AUTOSAR XML (schema 4-0-3)
package /ComponentTypes
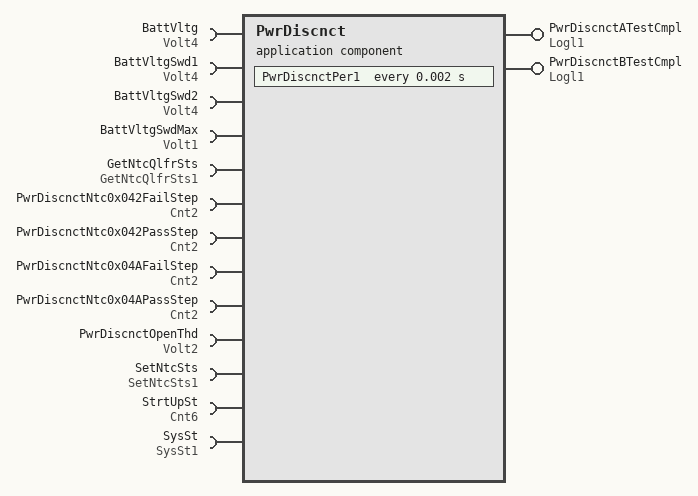
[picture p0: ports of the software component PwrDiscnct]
  application sw component type PwrDiscnct
    provide port PwrDiscnctATestCmpl: nonqueued-sender-com-spec{data-element=Logl, init-value=0}, provided-interface=Logl1  # Flag indicating that the Power Disconnect Sequence A is complete or not
    provide port PwrDiscnctBTestCmpl: nonqueued-sender-com-spec{data-element=Logl, init-value=0}, provided-interface=Logl1  # Flag indicating that the Power Disconnect Sequence B is complete or not
    13 x require port:
      BattVltg: nonqueued-receiver-com-spec{data-element=Val, filter=data-filter-type=ALWAYS, init-value=0}, required-interface=Volt4  # Battery Voltage
      BattVltgSwd1: nonqueued-receiver-com-spec{data-element=Val, filter=data-filter-type=ALWAYS, init-value=0}, required-interface=Volt4  # Switched Battery Voltage 1
      BattVltgSwd2: nonqueued-receiver-com-spec{data-element=Val, filter=data-filter-type=ALWAYS, init-value=0}, required-interface=Volt4  # Switched Battery Voltage 2
      BattVltgSwdMax: parameter-require-com-spec{init-value=16, parameter=Val}, required-interface=Volt1  # Maximum voltage at which switched voltage saturates
      GetNtcQlfrSts: required-interface=GetNtcQlfrSts1
      PwrDiscnctNtc0x042FailStep: parameter-require-com-spec{init-value=1024, parameter=Val}, required-interface=Cnt2
      PwrDiscnctNtc0x042PassStep: parameter-require-com-spec{init-value=4096, parameter=Val}, required-interface=Cnt2  # Power Disconnect NTC 0x042 Pass/N-Step
      PwrDiscnctNtc0x04AFailStep: parameter-require-com-spec{init-value=1024, parameter=Val}, required-interface=Cnt2  # Power Disconnect NTC 0x04A Fail Step
      PwrDiscnctNtc0x04APassStep: parameter-require-com-spec{init-value=4096, parameter=Val}, required-interface=Cnt2  # Power Disconnect NTC 0x04A Pass Step
      PwrDiscnctOpenThd: parameter-require-com-spec{init-value=2, parameter=Val}, required-interface=Volt2  # Power Disconnect Open Threshold - Voltage threshold for determining BattVltgSwd1 and BattVltgSwd2 is open
      SetNtcSts: required-interface=SetNtcSts1
      StrtUpSt: nonqueued-receiver-com-spec{data-element=Val, filter=data-filter-type=ALWAYS, init-value=0}, required-interface=Cnt6  # Start Up State
      SysSt: nonqueued-receiver-com-spec{data-element=Val, filter=data-filter-type=ALWAYS, init-value=3}, required-interface=SysSt1
    behavior PwrDiscnct_InternalBehavior: data-type-mapping=Nexteer
      ar-typed-per-instance-memorys:
        data PwrDiscnctDeltaVltg1: sw-calibration-access=READ-ONLY, type=Volt5  # Difference between Battery and Switched1 Voltage
        data PwrDiscnctDeltaVltg2: sw-calibration-access=READ-ONLY, type=Volt5  # Difference between Battery and Switched2 Voltage
        data PwrDiscnctSeqATestCmplPrev: sw-calibration-access=READ-ONLY, type=boolean  # Power Disconnect First Run Complete - Determines if the PwrDiscnctSequenceA has computes once per IGN Cycle
      timing event TMT_PwrDiscnctPer1: start-on-event=PwrDiscnctPer1, period=0.002
      runnable PwrDiscnctPer1
        data-receive-point-by-arguments:
          5 x access:
            REC_BattVltg_Val: accessed-variable=BattVltg.Val
            REC_BattVltgSwd1_Val: accessed-variable=BattVltgSwd1.Val
            REC_BattVltgSwd2_Val: accessed-variable=BattVltgSwd2.Val
            REC_StrtUpSt_Val: accessed-variable=StrtUpSt.Val
            REC_SysSt_Val: accessed-variable=SysSt.Val
        data-send-points:
          access SEND_PwrDiscnctATestCmpl_Logl: accessed-variable=PwrDiscnctATestCmpl.Logl
          access SEND_PwrDiscnctBTestCmpl_Logl: accessed-variable=PwrDiscnctBTestCmpl.Logl
        sync call SC_GetNtcQlfrSts1_Oper: operation=GetNtcQlfrSts.Oper, timeout=0
        sync call SC_SetNtcSts1_Oper: operation=SetNtcSts.Oper, timeout=0
  swc implementation PwrDiscnct_Implementation: behavior=PwrDiscnct_InternalBehavior
    code-descriptors:
      code Default: artifact-descriptors=autosar-engineering-object={short-label=Default, category=SWSRC}
